# STM32L15xxE register map
File version: 1.0
CPU: 
Registers are 32-bit, read-write, reset 0x0 unless marked. A register's access mark holds for its fields unless they carry their own. Offsets are from the block's base; [hi:lo] are bit positions; {n}, {i} and the like mark numbered series.

## EXTI — External interrupt/event controller
Base 0x40010400
0x00 IMR
  [22:0] MR — Interrupt mask on line x
0x04 EMR
  [22:0] MR — Event mask on line x
0x08 RTSR
  [22:0] TR — Rising edge trigger event configuration bit of line x
0x0C FTSR
  [22:0] TR — Falling edge trigger event configuration bit of line x
0x10 SWIER
  [22:0] SWIER — Software interrupt on line x
0x14 PR
  [22:0] PR — Pending bit

## Flash
Base 0x40023C00
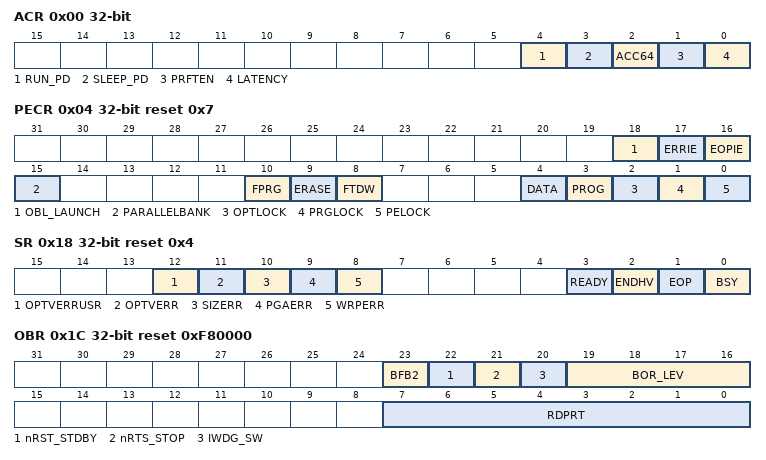
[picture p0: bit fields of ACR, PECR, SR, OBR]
0x00 ACR — Access control register
  [4] RUN_PD — Flash mode during Run
  [3] SLEEP_PD — Flash mode during Sleep
  [2] ACC64 — 64-bit access
  [1] PRFTEN — Prefetch enable
  [0] LATENCY
0x04 PECR reset 0x7 — Program/erase control register
  [18] OBL_LAUNCH — Launch the option byte loading
  [17] ERRIE — Error interrupt enable
  [16] EOPIE — End of programming interrupt enable
  [15] PARALLELBANK — Parallel bank mode
  [10] FPRG — Half Page/Double Word programming mode
  [9] ERASE — Page or Double Word erase mode
  [8] FTDW — Fixed time data write for Byte, Half Word and Word programming
  [4] DATA — Data EEPROM selection
  [3] PROG — Program memory selection
  [2] OPTLOCK — Option bytes block lock
  [1] PRGLOCK — Program memory lock
  [0] PELOCK — FLASH_PECR and data EEPROM lock
0x08 PDKEYR wo — Power down key register
  [31:0] PDKEYR — RUN_PD in FLASH_ACR key
0x0C PEKEYR wo — Program/erase key register
  [31:0] PEKEYR — FLASH_PEC and data EEPROM key
0x10 PRGKEYR wo — Program memory key register
  [31:0] PRGKEYR — Program memory key
0x14 OPTKEYR wo — Option byte key register
  [31:0] OPTKEYR — Option byte key
0x18 SR access per field reset 0x4 — Status register
  [12] OPTVERRUSR rw — Option UserValidity Error
  [11] OPTVERR rw — Option validity error
  [10] SIZERR rw — Size error
  [9] PGAERR rw — Programming alignment error
  [8] WRPERR rw — Write protected error
  [3] READY ro — Flash memory module ready after low power mode
  [2] ENDHV ro — End of high voltage
  [1] EOP ro — End of operation
  [0] BSY ro — Write/erase operations in progress
0x1C OBR ro reset 0xF80000 — Option byte register
  [23] BFB2 — Boot From Bank 2
  [22] nRST_STDBY
  [21] nRTS_STOP
  [20] IWDG_SW
  [19:16] BOR_LEV
  [7:0] RDPRT — Read protection
0x20 WRPR1 — Write protection register
  [31:0] WRP1 — Write protection
0x80 WRPR2 — Write protection register
  [31:0] WRP2
0x84 WRPR3 — Write protection register
  [31:0] WRP3

## GPIOE — General-purpose I/Os
Base 0x40021000
Same registers: GPIOC 0x40020800, GPIOD 0x40020C00, GPIOH 0x40021400, GPIOF 0x40021800, GPIOG 0x40021C00
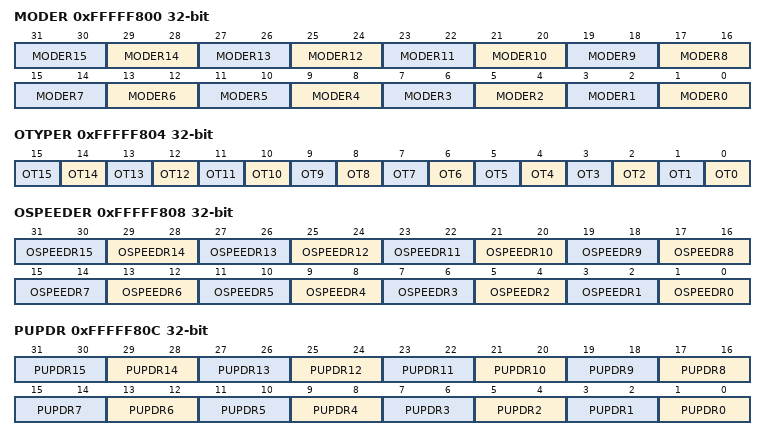
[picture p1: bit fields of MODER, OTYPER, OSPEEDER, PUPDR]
0xFFFFF800 MODER — GPIO port mode register
  [2n+1:2n] MODER{n} (n=0..15) — Port x configuration bits (y = 0..15)
0xFFFFF804 OTYPER — GPIO port output type register
  [n] OT{n} (n=0..15) — Port x configuration bits (y = 0..15)
0xFFFFF808 OSPEEDER — GPIO port output speed register
  [2n+1:2n] OSPEEDR{n} (n=0..15)
0xFFFFF80C PUPDR — GPIO port pull-up/pull-down register
  [2n+1:2n] PUPDR{n} (n=0..15) — Port x configuration bits (y = 0..15)
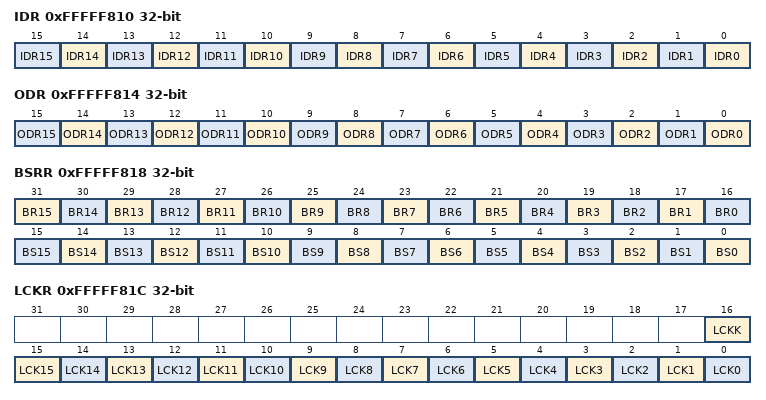
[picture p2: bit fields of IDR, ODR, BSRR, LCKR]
0xFFFFF810 IDR ro — GPIO port input data register
  [n] IDR{n} (n=0..15) — Port input data (y = 0..15)
0xFFFFF814 ODR — GPIO port output data register
  [n] ODR{n} (n=0..15) — Port output data (y = 0..15)
0xFFFFF818 BSRR wo — GPIO port bit set/reset register
  [n+16] BR{n} (n=1..15) — Port x reset bit y (y = 0..15)
  [16] BR0 — Port x set bit y (y= 0..15)
  [n] BS{n} (n=0..15) — Port x set bit y (y= 0..15)
0xFFFFF81C LCKR — GPIO port configuration lock register
  [16] LCKK — Port x lock bit y (y= 0..15)
  [n] LCK{n} (n=0..15) — Port x lock bit y (y= 0..15)
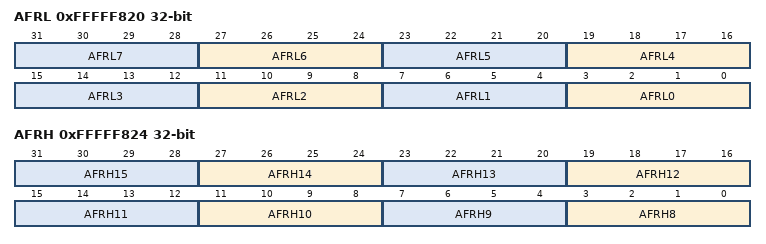
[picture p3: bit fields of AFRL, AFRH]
0xFFFFF820 AFRL
  [4n+3:4n] AFRL{n} (n=0..7) — Alternate function selection for port x bit y (y = 0..7)
0xFFFFF824 AFRH — GPIO alternate function high register
  [4n-29:4n-32] AFRH{n} (n=8..15) — Alternate function selection for port x bit y (y = 8..15)
